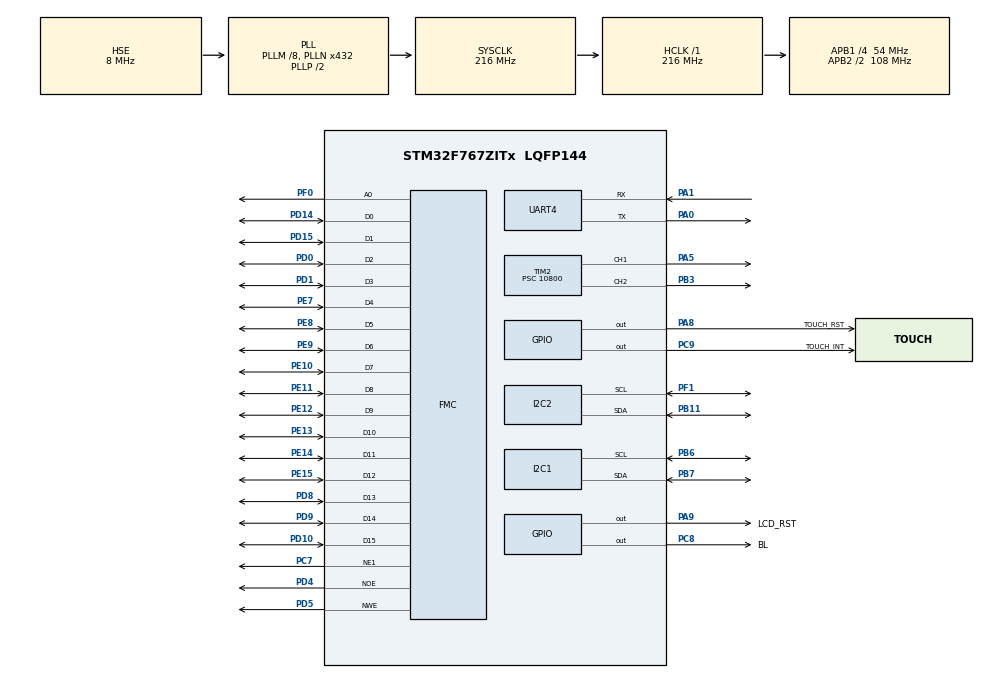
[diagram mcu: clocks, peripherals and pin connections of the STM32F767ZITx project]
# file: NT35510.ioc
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CORTEX_M7.ART_ACCLERATOR_ENABLE=1
CORTEX_M7.CPU_DCache=Enabled
CORTEX_M7.CPU_ICache=Enabled
CORTEX_M7.PREFETCH_ENABLE=1
FMC.AddressSetupTime1=2
FMC.BusTurnAroundDuration1=0
FMC.DataSetupTime1=5
I2C1.Timing=0x20404768
I2C2.Timing=0x20404768
Mcu.Family=STM32F7
Mcu.Name=STM32F767ZITx
Mcu.Package=LQFP144
NVIC.PriorityGroup=NVIC_PRIORITYGROUP_4
PA0/WKUP.Mode=Asynchronous
PA0/WKUP.Signal=UART4_TX
PA1.Mode=Asynchronous
PA1.Signal=UART4_RX
PA5.Signal=S_TIM2_CH1_ETR
PA8.GPIO_Label=TOUCH_RST
PA8.Signal=GPIO_Output
PA9.GPIO_Label=LCD_RST
PA9.Signal=GPIO_Output
PB11.Mode=I2C
PB11.Signal=I2C2_SDA
PB3.Signal=S_TIM2_CH2
PB6.Mode=I2C
PB6.Signal=I2C1_SCL
PB7.Mode=I2C
PB7.Signal=I2C1_SDA
PC14/OSC32_IN.Mode=LSE-External-Oscillator
PC14/OSC32_IN.Signal=RCC_OSC32_IN
PC15/OSC32_OUT.Mode=LSE-External-Oscillator
PC15/OSC32_OUT.Signal=RCC_OSC32_OUT
PC7.Mode=NorPsramChipSelect1_1
PC7.Signal=FMC_NE1
PC8.GPIO_Label=BL
PC8.GPIO_PuPd=GPIO_PULLUP
PC8.Signal=GPIO_Output
PC9.GPIO_Label=TOUCH_INT
PC9.Signal=GPIO_Output
PD0.Signal=FMC_D2_DA2
PD1.Signal=FMC_D3_DA3
PD10.Signal=FMC_D15_DA15
PD14.Signal=FMC_D0_DA0
PD15.Signal=FMC_D1_DA1
PD4.Signal=FMC_NOE
PD5.Signal=FMC_NWE
PD8.Signal=FMC_D13_DA13
PD9.Signal=FMC_D14_DA14
PE10.Signal=FMC_D7_DA7
PE11.Signal=FMC_D8_DA8
PE12.Signal=FMC_D9_DA9
PE13.Signal=FMC_D10_DA10
PE14.Signal=FMC_D11_DA11
PE15.Signal=FMC_D12_DA12
PE7.Signal=FMC_D4_DA4
PE8.Signal=FMC_D5_DA5
PE9.Signal=FMC_D6_DA6
PF0.Signal=FMC_A0
PF1.Mode=I2C
PF1.Signal=I2C2_SCL
PH0/OSC_IN.Mode=HSE-External-Clock-Source
PH0/OSC_IN.Signal=RCC_OSC_IN
PH1/OSC_OUT.Mode=HSE-External-Clock-Source
PH1/OSC_OUT.Signal=RCC_OSC_OUT
ProjectManager.HeapSize=0x200
ProjectManager.StackSize=0x400
ProjectManager.TargetToolchain=MDK-ARM V5
RCC.AHBFreq_Value=216000000
RCC.APB1CLKDivider=RCC_HCLK_DIV4
RCC.APB1Freq_Value=54000000
RCC.APB1TimFreq_Value=108000000
RCC.APB2CLKDivider=RCC_HCLK_DIV2
RCC.APB2Freq_Value=108000000
RCC.APB2TimFreq_Value=216000000
RCC.CortexFreq_Value=216000000
RCC.HCLKFreq_Value=216000000
RCC.HSE_VALUE=8000000
RCC.HSI_VALUE=16000000
RCC.PLLM=8
RCC.PLLN=432
RCC.PLLSourceVirtual=RCC_PLLSOURCE_HSE
RCC.SYSCLKFreq_VALUE=216000000
RCC.SYSCLKSource=RCC_SYSCLKSOURCE_PLLCLK
RCC.USBFreq_Value=216000000
RCC.VCOOutputFreq_Value=432000000
SH.FMC_A0.0=FMC_A0,A0_1
SH.FMC_D0_DA0.0=FMC_D0,16b-d1
SH.FMC_D10_DA10.0=FMC_D10,16b-d1
SH.FMC_D11_DA11.0=FMC_D11,16b-d1
SH.FMC_D12_DA12.0=FMC_D12,16b-d1
SH.FMC_D13_DA13.0=FMC_D13,16b-d1
SH.FMC_D14_DA14.0=FMC_D14,16b-d1
SH.FMC_D15_DA15.0=FMC_D15,16b-d1
SH.FMC_D1_DA1.0=FMC_D1,16b-d1
SH.FMC_D2_DA2.0=FMC_D2,16b-d1
SH.FMC_D3_DA3.0=FMC_D3,16b-d1
SH.FMC_D4_DA4.0=FMC_D4,16b-d1
SH.FMC_D5_DA5.0=FMC_D5,16b-d1
SH.FMC_D6_DA6.0=FMC_D6,16b-d1
SH.FMC_D7_DA7.0=FMC_D7,16b-d1
SH.FMC_D8_DA8.0=FMC_D8,16b-d1
SH.FMC_D9_DA9.0=FMC_D9,16b-d1
SH.FMC_NOE.0=FMC_NOE,Lcd1
SH.FMC_NWE.0=FMC_NWE,Lcd1
SH.S_TIM2_CH1_ETR.0=TIM2_CH1,PWM Generation1 CH1
SH.S_TIM2_CH2.0=TIM2_CH2,PWM Generation2 CH2
TIM2.Channel-PWM\ Generation1\ CH1=TIM_CHANNEL_1
TIM2.Channel-PWM\ Generation2\ CH2=TIM_CHANNEL_2
TIM2.Period=200
TIM2.Prescaler=10800
board=custom

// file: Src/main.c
/* USER CODE BEGIN Header */
/**
  ******************************************************************************
  * @file           : main.c
  * @brief          : Main program body
  ******************************************************************************
  * @attention
  *
  * <h2><center>&copy; Copyright (c) 2019 STMicroelectronics.
  * All rights reserved.</center></h2>
  *
  * This software component is licensed by ST under BSD 3-Clause license,
  * the "License"; You may not use this file except in compliance with the
  * License. You may obtain a copy of the License at:
  *                        opensource.org/licenses/BSD-3-Clause
  *
  ******************************************************************************
  */
/* USER CODE END Header */

#include "main.h"
#include "i2c.h"
#include "tim.h"
#include "usart.h"
#include "gpio.h"
#include "fmc.h"

/* USER CODE BEGIN Includes */
#include "nt35510_lcd.h"
/* USER CODE END Includes */

void SystemClock_Config(void);

int main(void)
{

  /* Enable I-Cache---------------------------------------------------------*/
  SCB_EnableICache();

  /* Enable D-Cache---------------------------------------------------------*/
  SCB_EnableDCache();

  /* MCU Configuration--------------------------------------------------------*/

  /* Reset of all peripherals, Initializes the Flash interface and the Systick. */
  HAL_Init();

  /* Configure the system clock */
  SystemClock_Config();

  /* Initialize all configured peripherals */
  MX_GPIO_Init();
  MX_FMC_Init();
  MX_I2C1_Init();
  MX_I2C2_Init();
  MX_TIM2_Init();
  MX_UART4_Init();
  /* USER CODE BEGIN 2 */
	NT35510_Init();
	HAL_TIM_PWM_Start(&htim2,TIM_CHANNEL_1);
	HAL_TIM_PWM_Start(&htim2,TIM_CHANNEL_2);
  /* USER CODE END 2 */

  /* Infinite loop */

  while (1)
  {

    /* USER CODE BEGIN 3 */
		TIM2->CCR1=20;
		TIM2->CCR2=10;
		NT35510_Clear(YELLOW);
  }
  /* USER CODE END 3 */
}

void SystemClock_Config(void)
{
  RCC_OscInitTypeDef RCC_OscInitStruct = {0};
  RCC_ClkInitTypeDef RCC_ClkInitStruct = {0};
  RCC_PeriphCLKInitTypeDef PeriphClkInitStruct = {0};

  /** Configure LSE Drive Capability
  */
  HAL_PWR_EnableBkUpAccess();
  /** Configure the main internal regulator output voltage
  */
  __HAL_RCC_PWR_CLK_ENABLE();
  __HAL_PWR_VOLTAGESCALING_CONFIG(PWR_REGULATOR_VOLTAGE_SCALE1);
  /** Initializes the CPU, AHB and APB busses clocks
  */
  RCC_OscInitStruct.OscillatorType = RCC_OSCILLATORTYPE_HSE;
  RCC_OscInitStruct.HSEState = RCC_HSE_BYPASS;
  RCC_OscInitStruct.PLL.PLLState = RCC_PLL_ON;
  RCC_OscInitStruct.PLL.PLLSource = RCC_PLLSOURCE_HSE;
  RCC_OscInitStruct.PLL.PLLM = 8;
  RCC_OscInitStruct.PLL.PLLN = 432;
  RCC_OscInitStruct.PLL.PLLP = RCC_PLLP_DIV2;
  RCC_OscInitStruct.PLL.PLLQ = 2;
  if (HAL_RCC_OscConfig(&RCC_OscInitStruct) != HAL_OK)
  {
    Error_Handler();
  }
  /** Activate the Over-Drive mode
  */
  if (HAL_PWREx_EnableOverDrive() != HAL_OK)
  {
    Error_Handler();
  }
  /** Initializes the CPU, AHB and APB busses clocks
  */
  RCC_ClkInitStruct.ClockType = RCC_CLOCKTYPE_HCLK|RCC_CLOCKTYPE_SYSCLK
                              |RCC_CLOCKTYPE_PCLK1|RCC_CLOCKTYPE_PCLK2;
  RCC_ClkInitStruct.SYSCLKSource = RCC_SYSCLKSOURCE_PLLCLK;
  RCC_ClkInitStruct.AHBCLKDivider = RCC_SYSCLK_DIV1;
  RCC_ClkInitStruct.APB1CLKDivider = RCC_HCLK_DIV4;
  RCC_ClkInitStruct.APB2CLKDivider = RCC_HCLK_DIV2;

  if (HAL_RCC_ClockConfig(&RCC_ClkInitStruct, FLASH_LATENCY_7) != HAL_OK)
  {
    Error_Handler();
  }
  PeriphClkInitStruct.PeriphClockSelection = RCC_PERIPHCLK_UART4|RCC_PERIPHCLK_I2C1
                              |RCC_PERIPHCLK_I2C2;
  PeriphClkInitStruct.Uart4ClockSelection = RCC_UART4CLKSOURCE_PCLK1;
  PeriphClkInitStruct.I2c1ClockSelection = RCC_I2C1CLKSOURCE_PCLK1;
  PeriphClkInitStruct.I2c2ClockSelection = RCC_I2C2CLKSOURCE_PCLK1;
  if (HAL_RCCEx_PeriphCLKConfig(&PeriphClkInitStruct) != HAL_OK)
  {
    Error_Handler();
  }
}

void Error_Handler(void)
{
}

/************************ (C) COPYRIGHT STMicroelectronics *****END OF FILE****/
